# NUC100DN_v1 register map
File version: 1.0
Registers are 32-bit, read-write, reset 0x0 unless marked. A register's access mark holds for its fields unless they carry their own. Offsets are from the block's base; [hi:lo] are bit positions; 'fields as' and 'values as' point back to an identical list.

## WWDT — WWDT Register Map
Base 0x40004100
0x00 WWDTRLD wo — Window Watchdog Timer Reload Counter Register
  [31:0] WWDTRLD — WWDT Reload Counter Register. Writing 0x00005AA5 to this register will reload the Window Watchdog Timer counter value to 0x3F. Note: Software can only write WWDTRLD to reload WWDT counter value when current WWDT counter value between 0 and WINCMP. If software writes WWDTRLD when current WWDT counter value is larger than WINCMP, WWDT reset signal will generate immediately.
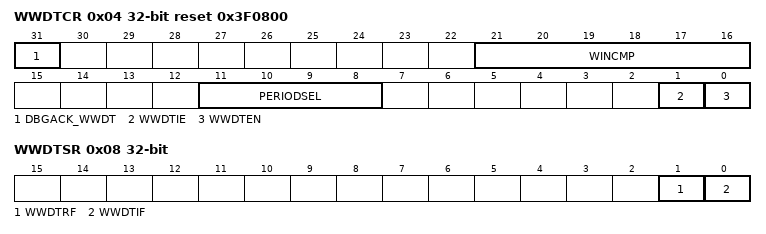
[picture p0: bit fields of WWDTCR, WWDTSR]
0x04 WWDTCR reset 0x3F0800 — Window Watchdog Timer Control Register
  [31] DBGACK_WWDT — ICE Debug Mode Acknowledge Disable Bit
    0=WWDT counter stopped if system is in Debug mode; 1=WWDT still counted even system is in Debug mode
  [21:16] WINCMP — WWDT Window Compare Register. Set this register to adjust the valid reload window. Note: Software can only write WWDTRLD to reload WWDT counter value when current WWDT counter value between 0 and WINCMP. If Software writes WWDTRLD when current WWDT counter value larger than WINCMP, WWDT reset signal will generate immediately.
  [11:8] PERIODSEL — WWDT Prescale Period Select. These 4-bit select the prescale period for the WWDT counter period.
    0=Pre-scale is 1; Max time-out period is 1 * 64 * WWDT_CLK; 1=Pre-scale is 2; Max time-out period is 2 * 64 * WWDT_CLK; 2=Pre-scale is 4; Max time-out period is 4 * 64 * WWDT_CLK; 3=Pre-scale is 8; Max time-out period is 8 * 64 * WWDT_CLK; 4=Pre-scale is 16; Max time-out period is 16 * 64 * WWDT_CLK; 5=Pre-scale is 32; Max time-out period is 32 * 64 * WWDT_CLK; 6=Pre-scale is 64; Max time-out period is 64 * 64 * WWDT_CLK; 7=Pre-scale is 128; Max time-out period is 128 * 64 * WWDT_CLK; 8=Pre-scale is 192; Max time-out period is 192 * 64 * WWDT_CLK; 9=Pre-scale is 256; Max time-out period is 256 * 64 * WWDT_CLK; 10=Pre-scale is 384; Max time-out period is 384 * 64 * WWDT_CLK; 11=Pre-scale is 512; Max time-out period is 512 * 64 * WWDT_CLK; 12=Pre-scale is 768; Max time-out period is 768 * 64 * WWDT_CLK; 13=Pre-scale is 1024; Max time-out period is 1024 * 64 * WWDT_CLK; 14=Pre-scale is 1536; Max time-out period is 1536 * 64 * WWDT_CLK; 15=Pre-scale is 2048; Max time-out period is 2048 * 64 * WWDT_CLK
  [1] WWDTIE — WWDT Interrupt Enable Bit. Set this bit to enable the Window Watchdog Timer time-out interrupt function.
    0=WWDT time-out interrupt function Disabled if WWDTIF (WWDTSR[0] WWDT compare match interrupt flag) is 1; 1=WWDT time-out interrupt function Enabled if WWDTIF (WWDTSR[0] WWDT compare match interrupt flag) is 1
  [0] WWDTEN — WWDT Enable Bit. Set this bit to enable Window Watchdog Timer counter counting.
    0=Window Watchdog Timer counter is stopped; 1=Window Watchdog Timer counter is starting counting
0x08 WWDTSR — Window Watchdog Timer Status Register
  [1] WWDTRF — WWDT Reset Flag. When WWDT counter counts down to 0 or writes WWDTRLD during current WWDT counter value being larger than WINCMP, chip will be reset and this bit is set to 1. This bit will be cleared to 0 by writing 1 to itself.
  [0] WWDTIF — WWDT Compare Match Interrupt Flag. When current WWDT counter value matches WWCMP, this bit is set to 1. This bit will be cleared by writing 1 to itself.
0x0C WWDTCVR ro reset 0x3F — Window Watchdog Timer Counter Value Register
  [5:0] WWDTCVAL — WWDT Counter Value (Read Only). This register reflects the current WWDT counter value.

## ACMP — ACMP Register Map
Base 0x400D0000
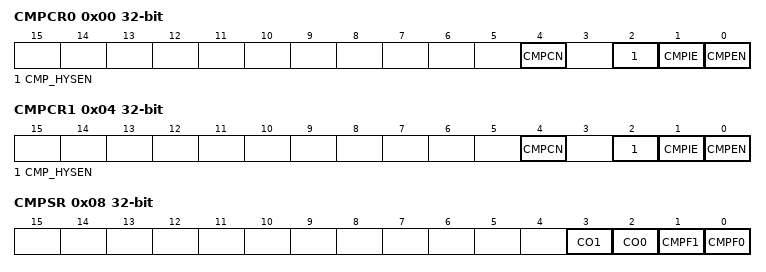
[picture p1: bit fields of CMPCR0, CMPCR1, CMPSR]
0x00 CMPCR0 — Comparator 0 Control Register
  [4] CMPCN — Comparator Negative Input Selection
    0=The source of the negative comparator input is from CPNx pin (x = 0. 1); 1=Internal band-gap reference voltage is selected as the source of negative comparator input
  [2] CMP_HYSEN — Comparator Hysteresis Enable Bit
    0=Hysteresis function Disabled (Default); 1=Hysteresis function Enabled. The typical range is 20mV
  [1] CMPIE — Comparator Interrupt Enable Bit
    0=Interrupt function Disabled; 1=Interrupt function Enabled
  [0] CMPEN — Comparator Enable Bit. Note: Comparator output needs to wait 2 us stable time after CMPEN is set.
    0=Comparator Disabled; 1=Comparator Enabled
0x04 CMPCR1 — Comparator 1 Control Register
  fields as CMPCR0
0x08 CMPSR — Comparator Status Register
  [3] CO1 — Comparator 1 Output
  [2] CO0 — Comparator 0 Output
  [1] CMPF1 — Comparator 1 Flag. This bit is set by hardware whenever the comparator 1 output changes state. This will cause an interrupt if CMPCR1[1] is set to 1. Note: This bit can be cleared by writing '1' to it.
  [0] CMPF0 — Comparator 0 Flag. This bit is set by hardware whenever the comparator 0 output changes state. This will cause an interrupt if CMPCR0[1] is set to 1. Note: This bit can be cleared by writing '1' to it.
